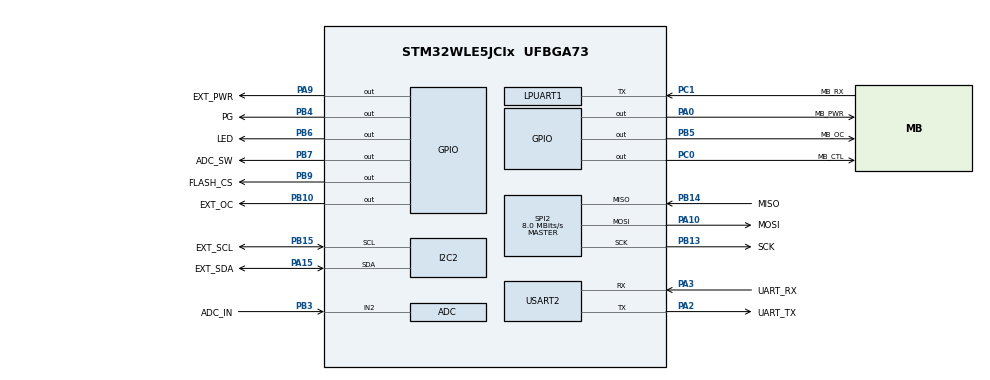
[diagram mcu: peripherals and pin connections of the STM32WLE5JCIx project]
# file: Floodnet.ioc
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ADC.NbrOfConversion=1
ADC.SelectedChannel=ADC_CHANNEL_2
I2C2.Timing=0x20303E5D
LPUART1.BaudRate=9600
LPUART1.FIFOMode=UART_FIFOMODE_ENABLE
LPUART1.Mode=UART_MODE_RX
LPUART1.SwapParam=UART_ADVFEATURE_SWAP_ENABLE
Mcu.Family=STM32WL
Mcu.Name=STM32WLE5JCIx
Mcu.Package=UFBGA73
NVIC.PriorityGroup=NVIC_PRIORITYGROUP_4
NVIC.TIM1_UP_IRQn=true\:15\:0\:false\:false\:true\:false\:true\:true
NVIC.TimeBase=TIM1_UP_IRQn
NVIC.TimeBaseIP=TIM1
PA0.GPIO_Label=MB_PWR
PA0.Signal=GPIO_Output
PA10.GPIO_Label=MOSI
PA10.Mode=Full_Duplex_Master
PA10.Signal=SPI2_MOSI
PA13.GPIO_Label=SWDIO
PA13.Mode=Serial_Wire
PA13.Signal=DEBUG_JTMS-SWDIO
PA14.GPIO_Label=SWCLK
PA14.Mode=Serial_Wire
PA14.Signal=DEBUG_JTCK-SWCLK
PA15.GPIO_Label=EXT_SDA
PA15.Mode=I2C
PA15.Signal=I2C2_SDA
PA2.GPIO_Label=UART_TX
PA2.Mode=Asynchronous
PA2.Signal=USART2_TX
PA3.GPIO_Label=UART_RX
PA3.Mode=Asynchronous
PA3.Signal=USART2_RX
PA9.GPIO_Label=EXT_PWR
PA9.Signal=GPIO_Output
PB10.GPIO_Label=EXT_OC
PB10.Signal=GPIO_Output
PB13.GPIO_Label=SCK
PB13.Mode=Full_Duplex_Master
PB13.Signal=SPI2_SCK
PB14.GPIO_Label=MISO
PB14.Mode=Full_Duplex_Master
PB14.Signal=SPI2_MISO
PB15.GPIO_Label=EXT_SCL
PB15.Mode=I2C
PB15.Signal=I2C2_SCL
PB3.GPIO_Label=ADC_IN
PB3.Mode=IN2
PB3.Signal=ADC_IN2
PB4.GPIO_Label=PG
PB4.Signal=GPIO_Output
PB5.GPIO_Label=MB_OC
PB5.Signal=GPIO_Output
PB6.GPIO_Label=LED
PB6.Signal=GPIO_Output
PB7.GPIO_Label=ADC_SW
PB7.Signal=GPIO_Output
PB9.GPIO_Label=FLASH_CS
PB9.Signal=GPIO_Output
PC0.GPIO_Label=MB_CTL
PC0.Signal=GPIO_Output
PC1.GPIO_Label=MB_RX
PC1.Mode=Half_duplex(single_wire_mode)
PC1.Signal=LPUART1_TX
ProjectManager.HeapSize=0x200
ProjectManager.StackSize=0x400
ProjectManager.TargetToolchain=STM32CubeIDE
RCC.AHBFreq_Value=48000000
RCC.APB1Freq_Value=48000000
RCC.APB1TimFreq_Value=48000000
RCC.APB2Freq_Value=48000000
RCC.APB2TimFreq_Value=48000000
RCC.APB3Freq_Value=48000000
RCC.CortexFreq_Value=48000000
RCC.HCLKFreq_Value=48000000
RCC.HSE_VALUE=8000000
RCC.HSI_VALUE=16000000
RCC.LPUART1CLockSelection=RCC_LPUART1CLKSOURCE_HSI
RCC.LSE_VALUE=32768
RCC.MSIClockRange=RCC_MSIRANGE_11
RCC.SYSCLKFreq_VALUE=48000000
RCC.VCOOutputFreq_Value=384000000
SPI2.CalculateBaudRate=8.0 MBits/s
SPI2.DataSize=SPI_DATASIZE_8BIT
SPI2.Direction=SPI_DIRECTION_2LINES
SPI2.Mode=SPI_MODE_MASTER
SPI2.VirtualType=VM_MASTER
USART2.VirtualMode-Asynchronous=VM_ASYNC
VP_SYS_VS_tim1.Mode=TIM1
board=custom

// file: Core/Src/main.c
/* USER CODE BEGIN Header */
/**
  ******************************************************************************
  * @file           : main.c
  * @brief          : Main program body
  ******************************************************************************
  * @attention
  *
  * Copyright (c) 2023 STMicroelectronics.
  * All rights reserved.
  *
  * This software is licensed under terms that can be found in the LICENSE file
  * in the root directory of this software component.
  * If no LICENSE file comes with this software, it is provided AS-IS.
  *
  ******************************************************************************
  */
/* USER CODE END Header */
#include "main.h"

ADC_HandleTypeDef hadc;

I2C_HandleTypeDef hi2c2;

UART_HandleTypeDef hlpuart1;
UART_HandleTypeDef huart2;

SPI_HandleTypeDef hspi2;

void SystemClock_Config(void);
static void MX_GPIO_Init(void);
static void MX_LPUART1_UART_Init(void);
static void MX_USART2_UART_Init(void);
static void MX_ADC_Init(void);
static void MX_I2C2_Init(void);
static void MX_SPI2_Init(void);

int main(void)
{

  /* MCU Configuration--------------------------------------------------------*/

  /* Reset of all peripherals, Initializes the Flash interface and the Systick. */
  HAL_Init();

  /* Configure the system clock */
  SystemClock_Config();

  /* Initialize all configured peripherals */
  MX_GPIO_Init();
  MX_LPUART1_UART_Init();
  MX_USART2_UART_Init();
  MX_ADC_Init();
  MX_I2C2_Init();
  MX_SPI2_Init();

  /* Infinite loop */
  while (1)
  {

  }
}

void SystemClock_Config(void)
{
  RCC_OscInitTypeDef RCC_OscInitStruct = {0};
  RCC_ClkInitTypeDef RCC_ClkInitStruct = {0};

  /** Configure the main internal regulator output voltage
  */
  __HAL_PWR_VOLTAGESCALING_CONFIG(PWR_REGULATOR_VOLTAGE_SCALE1);

  /** Initializes the CPU, AHB and APB buses clocks
  */
  RCC_OscInitStruct.OscillatorType = RCC_OSCILLATORTYPE_HSI|RCC_OSCILLATORTYPE_MSI;
  RCC_OscInitStruct.HSIState = RCC_HSI_ON;
  RCC_OscInitStruct.MSIState = RCC_MSI_ON;
  RCC_OscInitStruct.HSICalibrationValue = RCC_HSICALIBRATION_DEFAULT;
  RCC_OscInitStruct.MSICalibrationValue = RCC_MSICALIBRATION_DEFAULT;
  RCC_OscInitStruct.MSIClockRange = RCC_MSIRANGE_11;
  RCC_OscInitStruct.PLL.PLLState = RCC_PLL_NONE;
  if (HAL_RCC_OscConfig(&RCC_OscInitStruct) != HAL_OK)
  {
    Error_Handler();
  }

  /** Configure the SYSCLKSource, HCLK, PCLK1 and PCLK2 clocks dividers
  */
  RCC_ClkInitStruct.ClockType = RCC_CLOCKTYPE_HCLK3|RCC_CLOCKTYPE_HCLK
                              |RCC_CLOCKTYPE_SYSCLK|RCC_CLOCKTYPE_PCLK1
                              |RCC_CLOCKTYPE_PCLK2;
  RCC_ClkInitStruct.SYSCLKSource = RCC_SYSCLKSOURCE_MSI;
  RCC_ClkInitStruct.AHBCLKDivider = RCC_SYSCLK_DIV1;
  RCC_ClkInitStruct.APB1CLKDivider = RCC_HCLK_DIV1;
  RCC_ClkInitStruct.APB2CLKDivider = RCC_HCLK_DIV1;
  RCC_ClkInitStruct.AHBCLK3Divider = RCC_SYSCLK_DIV1;

  if (HAL_RCC_ClockConfig(&RCC_ClkInitStruct, FLASH_LATENCY_2) != HAL_OK)
  {
    Error_Handler();
  }
}

static void MX_ADC_Init(void)
{

  /** Configure the global features of the ADC (Clock, Resolution, Data Alignment and number of conversion)
  */
  hadc.Instance = ADC;
  hadc.Init.ClockPrescaler = ADC_CLOCK_SYNC_PCLK_DIV2;
  hadc.Init.Resolution = ADC_RESOLUTION_12B;
  hadc.Init.DataAlign = ADC_DATAALIGN_RIGHT;
  hadc.Init.ScanConvMode = ADC_SCAN_DISABLE;
  hadc.Init.EOCSelection = ADC_EOC_SINGLE_CONV;
  hadc.Init.LowPowerAutoWait = DISABLE;
  hadc.Init.LowPowerAutoPowerOff = DISABLE;
  hadc.Init.ContinuousConvMode = DISABLE;
  hadc.Init.NbrOfConversion = 1;
  hadc.Init.DiscontinuousConvMode = DISABLE;
  hadc.Init.ExternalTrigConv = ADC_SOFTWARE_START;
  hadc.Init.ExternalTrigConvEdge = ADC_EXTERNALTRIGCONVEDGE_NONE;
  hadc.Init.DMAContinuousRequests = DISABLE;
  hadc.Init.Overrun = ADC_OVR_DATA_PRESERVED;
  hadc.Init.SamplingTimeCommon1 = ADC_SAMPLETIME_1CYCLE_5;
  hadc.Init.SamplingTimeCommon2 = ADC_SAMPLETIME_1CYCLE_5;
  hadc.Init.OversamplingMode = DISABLE;
  hadc.Init.TriggerFrequencyMode = ADC_TRIGGER_FREQ_HIGH;
  if (HAL_ADC_Init(&hadc) != HAL_OK)
  {
    Error_Handler();
  }

}

static void MX_I2C2_Init(void)
{

  hi2c2.Instance = I2C2;
  hi2c2.Init.Timing = 0x20303E5D;
  hi2c2.Init.OwnAddress1 = 0;
  hi2c2.Init.AddressingMode = I2C_ADDRESSINGMODE_7BIT;
  hi2c2.Init.DualAddressMode = I2C_DUALADDRESS_DISABLE;
  hi2c2.Init.OwnAddress2 = 0;
  hi2c2.Init.OwnAddress2Masks = I2C_OA2_NOMASK;
  hi2c2.Init.GeneralCallMode = I2C_GENERALCALL_DISABLE;
  hi2c2.Init.NoStretchMode = I2C_NOSTRETCH_DISABLE;
  if (HAL_I2C_Init(&hi2c2) != HAL_OK)
  {
    Error_Handler();
  }

  /** Configure Analogue filter
  */
  if (HAL_I2CEx_ConfigAnalogFilter(&hi2c2, I2C_ANALOGFILTER_ENABLE) != HAL_OK)
  {
    Error_Handler();
  }

  /** Configure Digital filter
  */
  if (HAL_I2CEx_ConfigDigitalFilter(&hi2c2, 0) != HAL_OK)
  {
    Error_Handler();
  }

}

static void MX_LPUART1_UART_Init(void)
{

  hlpuart1.Instance = LPUART1;
  hlpuart1.Init.BaudRate = 9600;
  hlpuart1.Init.WordLength = UART_WORDLENGTH_8B;
  hlpuart1.Init.StopBits = UART_STOPBITS_1;
  hlpuart1.Init.Parity = UART_PARITY_NONE;
  hlpuart1.Init.Mode = UART_MODE_RX;
  hlpuart1.Init.HwFlowCtl = UART_HWCONTROL_NONE;
  hlpuart1.Init.OneBitSampling = UART_ONE_BIT_SAMPLE_DISABLE;
  hlpuart1.Init.ClockPrescaler = UART_PRESCALER_DIV1;
  hlpuart1.AdvancedInit.AdvFeatureInit = UART_ADVFEATURE_SWAP_INIT;
  hlpuart1.AdvancedInit.Swap = UART_ADVFEATURE_SWAP_ENABLE;
  if (HAL_HalfDuplex_Init(&hlpuart1) != HAL_OK)
  {
    Error_Handler();
  }
  if (HAL_UARTEx_SetTxFifoThreshold(&hlpuart1, UART_TXFIFO_THRESHOLD_1_8) != HAL_OK)
  {
    Error_Handler();
  }
  if (HAL_UARTEx_SetRxFifoThreshold(&hlpuart1, UART_RXFIFO_THRESHOLD_1_8) != HAL_OK)
  {
    Error_Handler();
  }
  if (HAL_UARTEx_EnableFifoMode(&hlpuart1) != HAL_OK)
  {
    Error_Handler();
  }

}

static void MX_USART2_UART_Init(void)
{

  huart2.Instance = USART2;
  huart2.Init.BaudRate = 115200;
  huart2.Init.WordLength = UART_WORDLENGTH_8B;
  huart2.Init.StopBits = UART_STOPBITS_1;
  huart2.Init.Parity = UART_PARITY_NONE;
  huart2.Init.Mode = UART_MODE_TX_RX;
  huart2.Init.HwFlowCtl = UART_HWCONTROL_NONE;
  huart2.Init.OverSampling = UART_OVERSAMPLING_16;
  huart2.Init.OneBitSampling = UART_ONE_BIT_SAMPLE_DISABLE;
  huart2.Init.ClockPrescaler = UART_PRESCALER_DIV1;
  huart2.AdvancedInit.AdvFeatureInit = UART_ADVFEATURE_NO_INIT;
  if (HAL_UART_Init(&huart2) != HAL_OK)
  {
    Error_Handler();
  }
  if (HAL_UARTEx_SetTxFifoThreshold(&huart2, UART_TXFIFO_THRESHOLD_1_8) != HAL_OK)
  {
    Error_Handler();
  }
  if (HAL_UARTEx_SetRxFifoThreshold(&huart2, UART_RXFIFO_THRESHOLD_1_8) != HAL_OK)
  {
    Error_Handler();
  }
  if (HAL_UARTEx_DisableFifoMode(&huart2) != HAL_OK)
  {
    Error_Handler();
  }

}

static void MX_SPI2_Init(void)
{

  /* SPI2 parameter configuration*/
  hspi2.Instance = SPI2;
  hspi2.Init.Mode = SPI_MODE_MASTER;
  hspi2.Init.Direction = SPI_DIRECTION_2LINES;
  hspi2.Init.DataSize = SPI_DATASIZE_8BIT;
  hspi2.Init.CLKPolarity = SPI_POLARITY_LOW;
  hspi2.Init.CLKPhase = SPI_PHASE_1EDGE;
  hspi2.Init.NSS = SPI_NSS_SOFT;
  hspi2.Init.BaudRatePrescaler = SPI_BAUDRATEPRESCALER_2;
  hspi2.Init.FirstBit = SPI_FIRSTBIT_MSB;
  hspi2.Init.TIMode = SPI_TIMODE_DISABLE;
  hspi2.Init.CRCCalculation = SPI_CRCCALCULATION_DISABLE;
  hspi2.Init.CRCPolynomial = 7;
  hspi2.Init.CRCLength = SPI_CRC_LENGTH_DATASIZE;
  hspi2.Init.NSSPMode = SPI_NSS_PULSE_ENABLE;
  if (HAL_SPI_Init(&hspi2) != HAL_OK)
  {
    Error_Handler();
  }

}

static void MX_GPIO_Init(void)
{
  GPIO_InitTypeDef GPIO_InitStruct = {0};

  /* GPIO Ports Clock Enable */
  __HAL_RCC_GPIOA_CLK_ENABLE();
  __HAL_RCC_GPIOB_CLK_ENABLE();
  __HAL_RCC_GPIOC_CLK_ENABLE();

  /*Configure GPIO pin Output Level */
  HAL_GPIO_WritePin(GPIOB, PG_Pin|ADC_SW_Pin|FLASH_CS_Pin|MB_OC_Pin
                          |LED_Pin|EXT_OC_Pin, GPIO_PIN_RESET);

  /*Configure GPIO pin Output Level */
  HAL_GPIO_WritePin(GPIOA, MB_PWR_Pin|EXT_PWR_Pin, GPIO_PIN_RESET);

  /*Configure GPIO pin Output Level */
  HAL_GPIO_WritePin(MB_CTL_GPIO_Port, MB_CTL_Pin, GPIO_PIN_RESET);

  /*Configure GPIO pins : PG_Pin ADC_SW_Pin FLASH_CS_Pin MB_OC_Pin
                           LED_Pin EXT_OC_Pin */
  GPIO_InitStruct.Pin = PG_Pin|ADC_SW_Pin|FLASH_CS_Pin|MB_OC_Pin
                          |LED_Pin|EXT_OC_Pin;
  GPIO_InitStruct.Mode = GPIO_MODE_OUTPUT_PP;
  GPIO_InitStruct.Pull = GPIO_NOPULL;
  GPIO_InitStruct.Speed = GPIO_SPEED_FREQ_LOW;
  HAL_GPIO_Init(GPIOB, &GPIO_InitStruct);

  /*Configure GPIO pins : MB_PWR_Pin EXT_PWR_Pin */
  GPIO_InitStruct.Pin = MB_PWR_Pin|EXT_PWR_Pin;
  GPIO_InitStruct.Mode = GPIO_MODE_OUTPUT_PP;
  GPIO_InitStruct.Pull = GPIO_NOPULL;
  GPIO_InitStruct.Speed = GPIO_SPEED_FREQ_LOW;
  HAL_GPIO_Init(GPIOA, &GPIO_InitStruct);

  /*Configure GPIO pin : MB_CTL_Pin */
  GPIO_InitStruct.Pin = MB_CTL_Pin;
  GPIO_InitStruct.Mode = GPIO_MODE_OUTPUT_PP;
  GPIO_InitStruct.Pull = GPIO_NOPULL;
  GPIO_InitStruct.Speed = GPIO_SPEED_FREQ_LOW;
  HAL_GPIO_Init(MB_CTL_GPIO_Port, &GPIO_InitStruct);

}

/* USER CODE BEGIN 4 */
ADC_HandleTypeDef *Get_AdcHandle(void)
{
  return &hadc;
}

UART_HandleTypeDef *Get_DebugHandle(void)
{
  return &huart2;
}

UART_HandleTypeDef *Get_SonarHandle(void)
{
  return &hlpuart1;
}

SPI_HandleTypeDef   *Get_SpiHandle(void)
{
  return &hspi2;
}

I2C_HandleTypeDef   *Get_I2cHandle(void)
{
  return &hi2c2;
}

/* USER CODE END 4 */

void HAL_TIM_PeriodElapsedCallback(TIM_HandleTypeDef *htim)
{
  if (htim->Instance == TIM1) {
    HAL_IncTick();
  }
}

void Error_Handler(void)
{
  __disable_irq();
  while (1)
  {
  }
}
